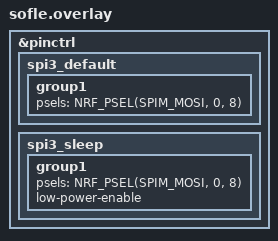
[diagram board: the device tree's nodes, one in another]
/*
 * RGB LED data is relocated to pro micro D0 (nice!nano P0.08), freeing
 * D1 (P0.06) for the nice!view CS pin. Overrides the stock sofle
 * nice_nano_v2 led_strip pinctrl, which uses P0.06.
 */

&pinctrl {
    spi3_default: spi3_default {
        group1 {
            psels = <NRF_PSEL(SPIM_MOSI, 0, 8)>;
        };
    };

    spi3_sleep: spi3_sleep {
        group1 {
            psels = <NRF_PSEL(SPIM_MOSI, 0, 8)>;
            low-power-enable;
        };
    };
};
